# max32620 register map
Vendor: Maxim Integrated; Series: ARMCM4; File version: 1.1
CPU: CM4 r1p0, little endian, no MPU, FPU, 3 interrupt priority bits
Registers are 32-bit, read-write, reset 0x0 unless marked. A register's access mark holds for its fields unless they carry their own. Offsets are from the block's base; [hi:lo] are bit positions.

## RTCTMR — Real Time Clock
Base 0x40000A00
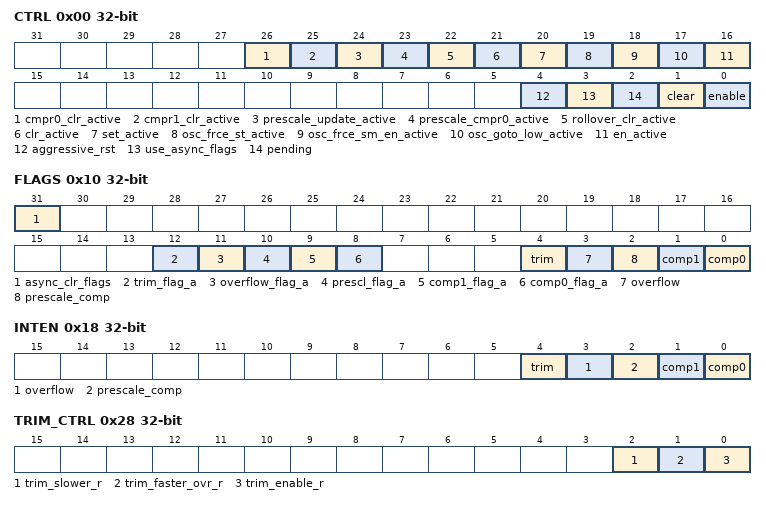
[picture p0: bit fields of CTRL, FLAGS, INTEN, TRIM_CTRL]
0x00 CTRL — RTC Timer Control
  [26] cmpr0_clr_active ro — cmpr0 clear transaction is pending
  [25] cmpr1_clr_active ro — cmpr1 clear transaction is pending
  [24] prescale_update_active ro — prescale update transaction is pending
  [23] prescale_cmpr0_active ro — prescale cmpr0 is pending
  [22] rollover_clr_active ro — rollover clr is pending
  [21] clr_active ro — RTC clear is pending
  [20] set_active ro — timer_set_active
  [19] osc_frce_st_active ro — osc_force_state transaction is pending
  [18] osc_frce_sm_en_active ro — osc_force_mode transaction is pending
  [17] osc_goto_low_active ro — osc_goto_low_r transaction is pending
  [16] en_active ro — Enable RTC in Active Modes
  [4] aggressive_rst — Use Aggressive Reset Mode
  [3] use_async_flags — Use Async RTC Flags
  [2] pending ro — RTC Transaction Pending
  [1] clear wo — RTC Timer Clear Bit
  [0] enable — RTC Timer Enable
0x04 TIMER — RTC Timer Count Value
0x08 COMP0 — RTC Time of Day Alarm 0 Compare Register
0x0C COMP1 — RTC Time of Day Alarm 1 Compare Register
0x10 FLAGS — CPU Interrupt and RTC Domain Flags
  [31] async_clr_flags wo — Asynchronous RTC Flag Clear
  [12] trim_flag_a ro — RTC Trim Event 4kHz Flag
  [11] overflow_flag_a ro — RTC Overflow 4kHz Flag
  [10] prescl_flag_a ro — RTC Prescale Compare 4kHz Flag
  [9] comp1_flag_a ro — RTC Compare 1 4kHz Flag
  [8] comp0_flag_a ro — RTC Compare 0 4kHz Flag
  [4] trim write-1-clears — RTC Trim Interrupt Status
  [3] overflow write-1-clears — RTC Overflow Interrupt Status
  [2] prescale_comp write-1-clears — RTC Prescale Compare Int Status
  [1] comp1 write-1-clears — RTC Compare 1 Interrupt Status
  [0] comp0 write-1-clears — RTC Compare 0 Interrupt Status
0x14 SNZ_VALUE — RTC Timer Alarm Snooze Value
0x18 INTEN — Interrupt Enable Controls
  [4] trim — RTC Trim Adjust Event Interrupt Enable
  [3] overflow — RTC Overflow Interrupt Enable
  [2] prescale_comp — RTC Prescale Compare Int Enable
  [1] comp1 — RTC Time of Day Alarm (Compare 1) Interrupt Enable
  [0] comp0 — RTC Time of Day Alarm (Compare 0) Interrupt Enable
0x1C PRESCALE — RTC Timer Prescale Setting
  [3:0] width_selection
0x24 PRESCALE_MASK — RTC Timer Prescale Compare Mask
  [3:0] comp_mask
0x28 TRIM_CTRL — RTC Timer Trim Controls
  [2] trim_slower_r ro — RTC Trim Direction Status
  [1] trim_faster_ovr_r — Force RTC Trim to Faster
  [0] trim_enable_r — Enable RTL Trim of RTC Timer
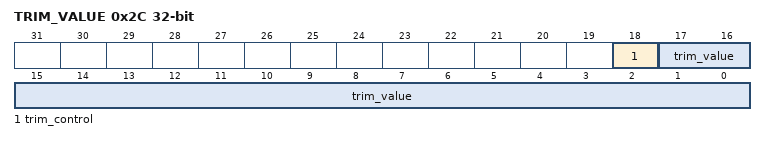
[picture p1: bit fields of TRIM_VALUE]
0x2C TRIM_VALUE — RTC Timer Trim Adjustment Interval
  [18] trim_control — Trim Direction
  [17:0] trim_value — Trim PPM Value

## RTCCFG — RTC Configuration Register
Base 0x40000A70
0x00 NANO_CNTR — Nano Oscillator Counter Read Register
  [15:0] nanoring_counter ro — Nano Oscillator Counter
0x04 CLK_CTRL — RTC Clock Control Settings
  [2] nano_en — Enable nanoring oscillator output
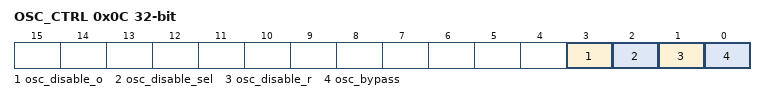
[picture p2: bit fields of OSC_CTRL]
0x0C OSC_CTRL — RTC Oscillator Control
  [3] osc_disable_o ro — Reset RTC Oscillator
  [2] osc_disable_sel — Select RTC Oscillator Disable Control Source
    0=PwrSeq_Control (PowerSequencer controls the reset state of the RTC); 1=RTC_Domain_Control (RTC reset controlled by osc_disable_r bit)
  [1] osc_disable_r — if osc_disable_sel = 1, this will hold the RTC in reset.
  [0] osc_bypass — Bypass RTC oscillator

## ICC — Instruction Cache Controller
Base 0x40003000
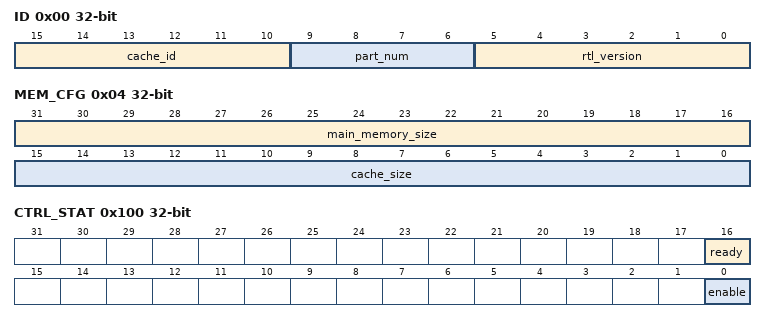
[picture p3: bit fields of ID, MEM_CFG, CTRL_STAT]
0x00 ID — Device ID Register
  [15:10] cache_id ro
  [9:6] part_num ro — Part Number ID
  [5:0] rtl_version ro — RTL Release Version
0x04 MEM_CFG — Memory Configuration Register
  [31:16] main_memory_size ro — Internal Flash Memory Size
  [15:0] cache_size ro — Instruction Cache Size
0x100 CTRL_STAT — Control and Status
  [16] ready ro — Cache Ready Status
  [0] enable — Cache Enable
0x700 INVDT_ALL — Invalidate (Clear) Cache Control
